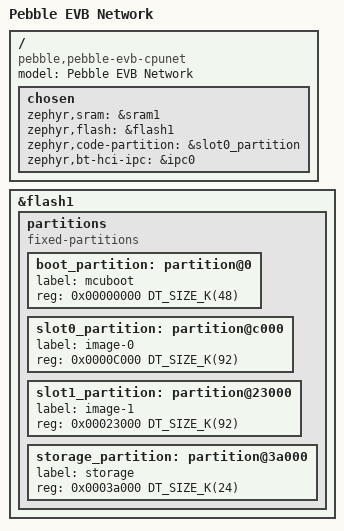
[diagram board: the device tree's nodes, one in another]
/dts-v1/;

#include <nordic/nrf5340_cpunet_qkaa.dtsi>
#include "pebble_evb_nrf5340_cpunet-pinctrl.dtsi"

/ {
	model = "Pebble EVB Network";
	compatible = "pebble,pebble-evb-cpunet";

	chosen {
		zephyr,sram = &sram1;
		zephyr,flash = &flash1;
		zephyr,code-partition = &slot0_partition;
		zephyr,bt-hci-ipc = &ipc0;
	};
};

&flash1 {
	partitions {
		compatible = "fixed-partitions";
		#address-cells = <1>;
		#size-cells = <1>;

		boot_partition: partition@0 {
			label = "mcuboot";
			reg = <0x00000000 DT_SIZE_K(48)>;
		};
		slot0_partition: partition@c000 {
			label = "image-0";
			reg = <0x0000C000 DT_SIZE_K(92)>;
		};
		slot1_partition: partition@23000 {
			label = "image-1";
			reg = <0x00023000 DT_SIZE_K(92)>;
		};
		storage_partition: partition@3a000 {
			label = "storage";
			reg = <0x0003a000 DT_SIZE_K(24)>;
		};
	};
};

#include <common/nordic/nrf5340_shared_sram_partition.dtsi>
